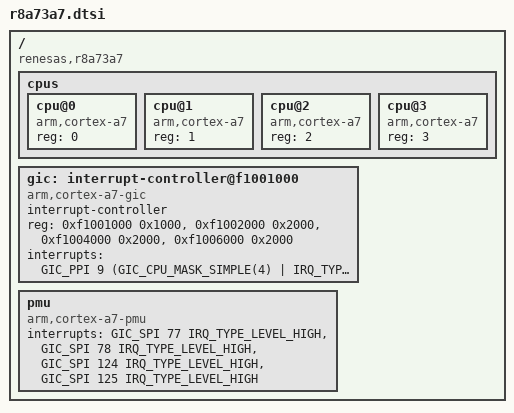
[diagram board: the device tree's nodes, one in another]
/*
 * Device Tree Source for the r8a73a7 SoC
 *
 * Copyright (C) 2014 Broadcom India Research
 *
 * This file is licensed under the terms of the GNU General Public License
 * version 2.  This program is licensed "as is" without any warranty of any
 * kind, whether express or implied.
 */

#include "u2-common.dtsi"

/{
	compatible = "renesas,r8a73a7";

	cpus {
		#address-cells = <1>;
		#size-cells = <0>;

		cpu@0 {
			device_type = "cpu";
			compatible = "arm,cortex-a7";
			reg = <0>;
		};

		cpu@1 {
			device_type = "cpu";
			compatible = "arm,cortex-a7";
			reg = <1>;
		};

		cpu@2 {
			device_type = "cpu";
			compatible = "arm,cortex-a7";
			reg = <2>;
		};

		cpu@3 {
			device_type = "cpu";
			compatible = "arm,cortex-a7";
			reg = <3>;
		};

	};

	gic: interrupt-controller@f1001000 {
		compatible = "arm,cortex-a7-gic", "arm,cortex-a15-gic";
		interrupt-controller;
		reg = <0xf1001000 0x1000>,
		      <0xf1002000 0x2000>,
		      <0xf1004000 0x2000>,
		      <0xf1006000 0x2000>;
		interrupts = <GIC_PPI 9 (GIC_CPU_MASK_SIMPLE(4) | IRQ_TYPE_LEVEL_HIGH)>;
		#interrupt-cells = <3>;
	};

	pmu {
		compatible = "arm,cortex-a7-pmu";
		interrupts = <GIC_SPI 77 IRQ_TYPE_LEVEL_HIGH>,
			     <GIC_SPI 78 IRQ_TYPE_LEVEL_HIGH>,
			     <GIC_SPI 124 IRQ_TYPE_LEVEL_HIGH>,
			     <GIC_SPI 125 IRQ_TYPE_LEVEL_HIGH>;
	};
};
